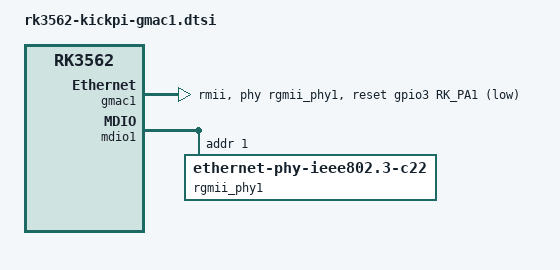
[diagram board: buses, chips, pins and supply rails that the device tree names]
&gmac1 {
        phy-mode = "rmii";
        clock_in_out = "input";

        snps,reset-gpio = <&gpio3 RK_PA1 GPIO_ACTIVE_LOW>;
        snps,reset-active-low;
        snps,reset-delays-us = <0 20000 100000>;

        tx_delay = <0x10>;
        rx_delay = <0x2f>;

        pinctrl-names="default";
        pinctrl-0 = <&rmii_pins>;

        phy-handle = <&rgmii_phy1>;

        status = "okay";
};

&mdio1 {
        rgmii_phy1: phy@1 {
                compatible = "ethernet-phy-ieee802.3-c22";
                reg = <0x01>;
        };
};

